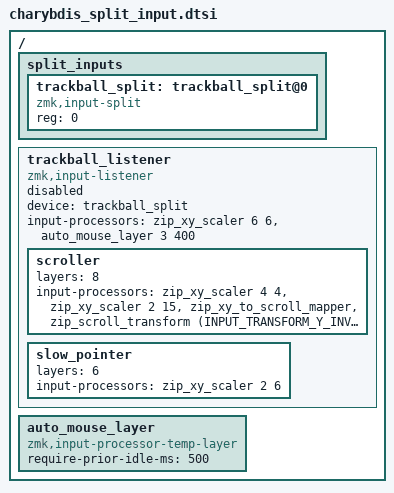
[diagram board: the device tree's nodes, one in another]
// Split input configuration for Charybdis dongle
// Defines ONLY the split input infrastructure needed by the dongle (central)
// Does NOT include SPI/trackball hardware (that's in charybdis_pmw3610.dtsi for the right half)

#include <dt-bindings/zmk/input_transform.h>
#include <input/processors.dtsi>

/ {
    split_inputs {
        #address-cells = <1>;
        #size-cells = <0>;

        trackball_split: trackball_split@0 {
            compatible = "zmk,input-split";
            reg = <0>;
        };
    };

    trackball_listener: trackball_listener {
        compatible = "zmk,input-listener";
        status = "disabled";
        device = <&trackball_split>;

        /* base processor chain - sensitivity and auto mouse layer */
        input-processors = <&zip_xy_scaler 6 6 &auto_mouse_layer 3 400>;

        /* layer-8 scroll override */
        scroller {
            layers = <8>;
            input-processors = <
                &zip_xy_scaler 4 4
                &zip_xy_scaler 2 15
                &zip_xy_to_scroll_mapper
                &zip_scroll_transform (INPUT_TRANSFORM_Y_INVERT)
            >;
        };

        /* layer-6 slow-pointer override */
        slow_pointer {
            layers = <6>;
            input-processors = <&zip_xy_scaler 2 6>;
        };
    };

    /* Auto mouse layer processor - activates layer 3 when trackball moves */
    auto_mouse_layer: auto_mouse_layer {
        compatible = "zmk,input-processor-temp-layer";
        #input-processor-cells = <2>;
        require-prior-idle-ms = <500>;
    };
};
